# STM32WL5X_CM0P register map
File version: 2.1
CPU: CM0 r0p1, little endian, MPU, no FPU, 4 interrupt priority bits
Registers are 32-bit, read-write, reset 0x0 unless marked. A register's access mark holds for its fields unless they carry their own. Offsets are from the block's base; [hi:lo] are bit positions; {n}, {i} and the like mark numbered series; 'fields as' and 'values as' point back to an identical list.

## DMAMUX — DMA request multiplexer
Base 0x40020800
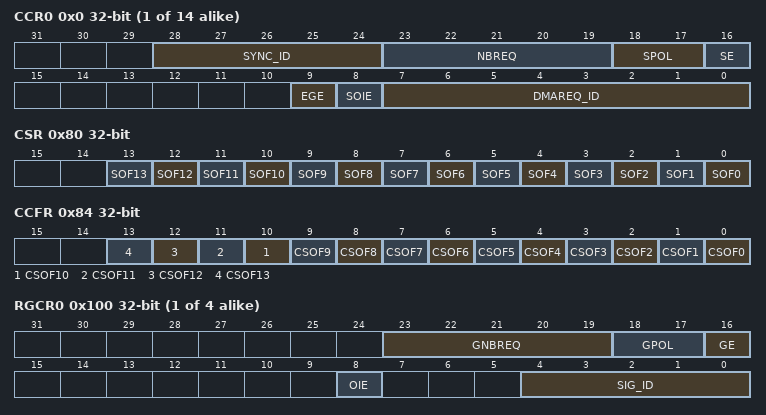
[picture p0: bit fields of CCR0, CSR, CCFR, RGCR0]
{0x0+4i} CCR{i} (i=0..13) — DMA Multiplexer Channel {i} Control register
  [28:24] SYNC_ID — Synchronization identification
    {v}=exti{v} (Signal `EXTIx` selected as synchronization input) (v=0..15); 16=dmamux1_evt0 (Signal `dmamux1_evt0` selected as synchronization input); 17=dmamux1_evt1 (Signal `dmamux1_evt1` selected as synchronization input); 18=lptim1_out (Signal `lptim1_out` selected as synchronization input); 19=lptim2_out (Signal `lptim2_out` selected as synchronization input); 20=lptim3_out (Signal `lptim3_out` selected as synchronization input)
  [23:19] NBREQ — Number of DMA requests minus 1 to forward
  [18:17] SPOL — Synchronization polarity
    0=NoEdge (No event, i.e. no synchronization nor detection); 1=RisingEdge; 2=FallingEdge; 3=BothEdges (Rising and falling edges)
  [16] SE — Synchronization enable
    0=Disabled (Synchronization disabled); 1=Enabled (Synchronization enabled)
  [9] EGE — Event generation enable
    0=Disabled (Event generation disabled); 1=Enabled (Event generation enabled)
  [8] SOIE — Synchronization overrun interrupt enable
    0=Disabled (Synchronization overrun interrupt disabled); 1=Enabled (Synchronization overrun interrupt enabled)
  [7:0] DMAREQ_ID — DMA request identification
    0=none (No signal selected as request input); {v}=dmamux1_req_gen{v-1} (Signal `dmamux1_req_gen{v-1}` selected as request input) (v=1..4); 5=adc (Signal `adc1_dma` selected as request input); 6=dat_out1 (Signal `dac_out1_dma` selected as request input); 7=spi1_rx_dma (Signal `spi1_rx_dma` selected as request input); 8=spi1_tx_dma (Signal `spi1_tx_dma` selected as request input); 9=spi2_rx_dma (Signal `spi2_rx_dma` selected as request input); 10=spi2_tx_dma (Signal `spi2_tx_dma` selected as request input); 11=i2c1_rx_dma (Signal `i2c1_rx_dma` selected as request input); 12=i2c1_tx_dma (Signal `i2c1_tx_dma` selected as request input); 13=i2c2_rx_dma (Signal `i2c2_rx_dma` selected as request input); 14=i2c2_tx_dma (Signal `i2c2_tx_dma` selected as request input); 15=i2c3_rx_dma (Signal `i2c3_rx_dma` selected as request input); 16=i2c3_tx_dma (Signal `i2c3_tx_dma` selected as request input); 17=usart1_rx_dma (Signal `usart1_rx_dma` selected as request input); 18=usart1_tx_dma (Signal `usart1_tx_dma` selected as request input); 19=usart2_rx_dma (Signal `usart2_rx_dma` selected as request input); 20=usart2_tx_dma (Signal `usart2_tx_dma` selected as request input); 21=lpuart1_rx_dma (Signal `lpuart1_rx_dma` selected as request input); 22=lpuart1_tx_dma (Signal `lpuart1_tx_dma` selected as request input); {v}=tim1_ch{v-22} (Signal `tim1_ch{v-22}` selected as request input) (v=23..26); 27=tim1_up (Signal `tim1_up` selected as request input); 28=tim1_trig (Signal `tim1_trig` selected as request input); 29=tim1_com (Signal `tim1_com` selected as request input); {v}=tim2_ch{v-29} (Signal `tim2_ch{v-29}` selected as request input) (v=30..33); 34=tim2_up (Signal `tim2_up` selected as request input); 35=tim16_ch1 (Signal `tim16_ch1` selected as request input); 36=tim16_up (Signal `tim16_up` selected as request input); 37=tim17_ch1 (Signal `tim17_ch1` selected as request input); 38=tim17_up (Signal `tim17_up` selected as request input); 39=aes_in (Signal `aes_in` selected as request input); 40=aes_out (Signal `aes_out` selected as request input); 41=subghzspi_rx (Signal `subghzspi_rx` selected as request input); 42=subghzspi_tx (Signal `subghzspi_tx` selected as request input)
0x80 CSR ro — request line multiplexer interrupt channel status register
  [n] SOF{n} (n=0..13) — Synchronization Overrun Flag {n}
    0=NoSyncEvent (No synchronization event occured on a DMA request line multiplexer channel x, while the DMA request counter value is lower than NBREQ); 1=SyncEvent (Synchronization event occured on a DMA request line multiplexer channel x, while the DMA request counter value is lower than NBREQ)
0x84 CCFR wo — request line multiplexer interrupt channel clear flag register
  [n] CSOF{n} (n=0..13) write-1-clears — Synchronization Clear Overrun Flag {n}
    1=Clear synchronization flag
{0x100+4i} RGCR{i} (i=0..3) — request generator channel x configuration register
  [23:19] GNBREQ — Number of DMA requests to be generated (minus 1)
  [18:17] GPOL — DMA request generator trigger polarity
    0=NoEdge (No event, i.e. no detection nor generation); 1=RisingEdge; 2=FallingEdge; 3=BothEdges (Rising and falling edges)
  [16] GE — DMA request generator channel x enable
    0=Disabled (DMA request generation disabled); 1=Enabled (DMA request enabled)
  [8] OIE — Trigger overrun interrupt enable
    0=Disabled (Trigger overrun interrupt disabled); 1=Enabled (Trigger overrun interrupt enabled)
  [4:0] SIG_ID — Signal identification
    values as CCR0.SYNC_ID
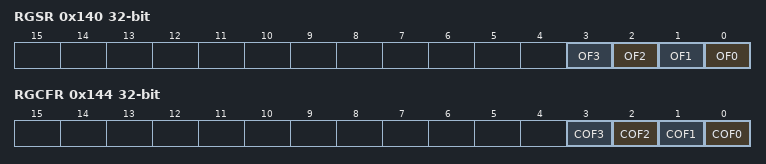
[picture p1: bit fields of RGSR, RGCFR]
0x140 RGSR ro — request generator interrupt status register
  [n] OF{n} (n=0..3) — Generator Overrun Flag {n}
    0=NoTrigger (No new trigger event occured on DMA request generator channel x, before the request counter underrun); 1=Trigger (New trigger event occured on DMA request generator channel x, before the request counter underrun)
0x144 RGCFR wo — request generator interrupt clear flag register
  [n] COF{n} (n=0..3) write-1-clears — Generator Clear Overrun Flag {n}
    1=Clear overrun flag
